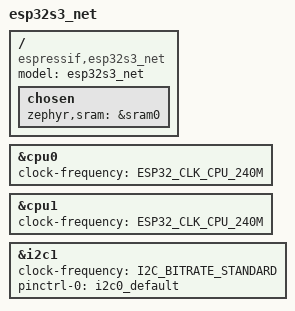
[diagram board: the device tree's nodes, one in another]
/*
 * Copyright (c) 2022 Espressif Systems (Shanghai) Co., Ltd.
 *
 * SPDX-License-Identifier: Apache-2.0
 */
/dts-v1/;

#include <espressif/esp32s3.dtsi>
#include "esp32s3_net-pinctrl.dtsi"
/ {
	model = "esp32s3_net";
	compatible = "espressif,esp32s3_net";


	chosen {
		zephyr,sram = &sram0;
	};

};

&cpu0 {
	clock-frequency = <ESP32_CLK_CPU_240M>;
};

&cpu1 {
	clock-frequency = <ESP32_CLK_CPU_240M>;
};

&i2c1 {
	clock-frequency = <I2C_BITRATE_STANDARD>;
	pinctrl-0 = <&i2c0_default>;
	pinctrl-names = "default";
};
